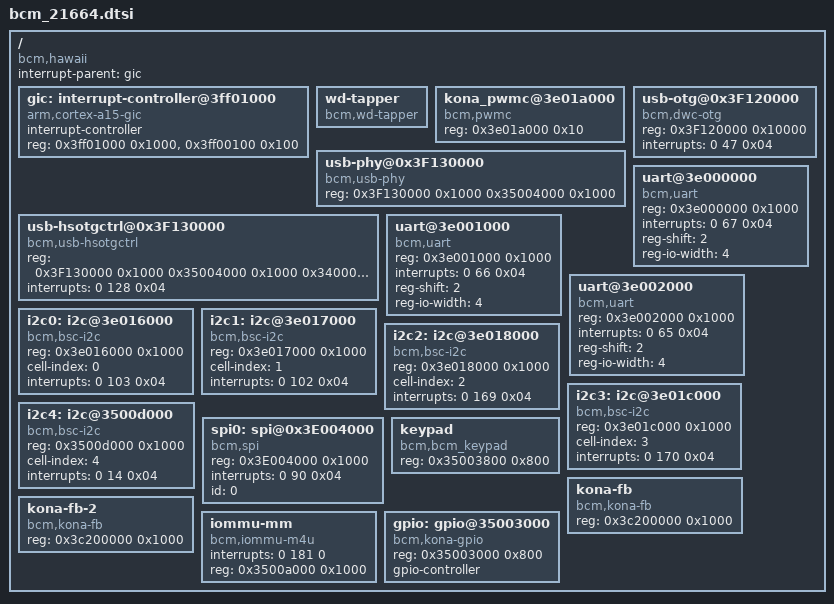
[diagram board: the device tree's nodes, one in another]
/* Generic BCM_21664 Device tree file */

/ {
	#address-cells = <1>;
	#size-cells = <1>;
	compatible = "bcm,hawaii";
	interrupt-parent = <&gic>;

	gic: interrupt-controller@3ff01000 {
		compatible = "arm,cortex-a15-gic", "arm,cortex-a9-gic";
		#interrupt-cells = <3>;
		#address-cells = <0>;
		interrupt-controller;
		reg = <0x3ff01000 0x1000>,
		      <0x3ff00100 0x100>;
	};

	wd-tapper {
		compatible = "bcm,wd-tapper";
	};

	kona_pwmc@3e01a000 {
		compatible = "bcm,pwmc";
		reg = <0x3e01a000 0x10>;
	};

	usb-phy@0x3F130000 {
		compatible = "bcm,usb-phy";
		reg = <0x3F130000 0x1000
			0x35004000 0x1000>;
	};

	usb-hsotgctrl@0x3F130000 {
		compatible = "bcm,usb-hsotgctrl";
		reg = <0x3F130000 0x1000
			0x35004000 0x1000
			0x34000000 0x1000>;
		interrupts = <0 128 0x04>;
	};

	usb-otg@0x3F120000 {
		compatible = "bcm,dwc-otg";
		reg = <0x3F120000 0x10000>;
		interrupts = <0 47 0x04>;
	};


	uart@3e000000 {
		compatible = "bcm,uart";
		reg = <0x3e000000 0x1000>;
		interrupts = <0 67 0x04>;
		reg-shift = <2>;
		reg-io-width = <4>;
	};

	uart@3e001000 {
		compatible = "bcm,uart";
		reg = <0x3e001000 0x1000>;
		interrupts = <0 66 0x04>;
		reg-shift = <2>;
		reg-io-width = <4>;
	};

	uart@3e002000 {
		compatible = "bcm,uart";
		reg = <0x3e002000 0x1000>;
		interrupts = <0 65 0x04>;
		reg-shift = <2>;
		reg-io-width = <4>;
	};

	i2c0: i2c@3e016000 {
		compatible = "bcm,bsc-i2c";
		reg = <0x3e016000 0x1000>;
		#address-cells = <1>;
		#size-cells = <0>;
		cell-index = <0>;
		interrupts = <0 103 0x04>;
	};

	i2c1: i2c@3e017000 {
		compatible = "bcm,bsc-i2c";
		reg = <0x3e017000 0x1000>;
		#address-cells = <1>;
		#size-cells = <0>;
		cell-index = <1>;
		interrupts = <0 102 0x04>;
	};

	i2c2: i2c@3e018000 {
		compatible = "bcm,bsc-i2c";
		reg = <0x3e018000 0x1000>;
		#address-cells = <1>;
		#size-cells = <0>;
		cell-index = <2>;
		interrupts = <0 169 0x04>;
	};

	i2c3: i2c@3e01c000 {
		compatible = "bcm,bsc-i2c";
		reg = <0x3e01c000 0x1000>;
		#address-cells = <1>;
		#size-cells = <0>;
		cell-index = <3>;
		interrupts = <0 170 0x04>;
	};

	i2c4: i2c@3500d000 {
		compatible = "bcm,bsc-i2c";
		reg = <0x3500d000 0x1000>;
		#address-cells = <1>;
		#size-cells = <0>;
		cell-index = <4>;
		interrupts = <0 14 0x04>;
	};

	spi0: spi@0x3E004000 {
		compatible = "bcm,spi";
		#address-cells = <1>;
		#size-cells = <0>;
		reg = <0x3E004000 0x1000>;
		interrupts = <0 90 0x04>;
		id = <0>;
	};

	keypad {
		compatible = "bcm,bcm_keypad" ;
		reg = <0x35003800 0x800>;
	};

	kona-fb {
		compatible = "bcm,kona-fb";
		reg = <0x3c200000 0x1000>;
	};

	kona-fb-2 {
		compatible = "bcm,kona-fb";
		reg = <0x3c200000 0x1000>;
	};


	iommu-mm {
		compatible = "bcm,iommu-m4u";
		interrupts = <0 181 0>;
		reg = <0x3500a000 0x1000>;
	};

	gpio: gpio@35003000 {
		compatible = "bcm,kona-gpio";
		reg = <0x35003000 0x800>;
		#gpio-cells = <2>;
		gpio-controller;
	};
};
